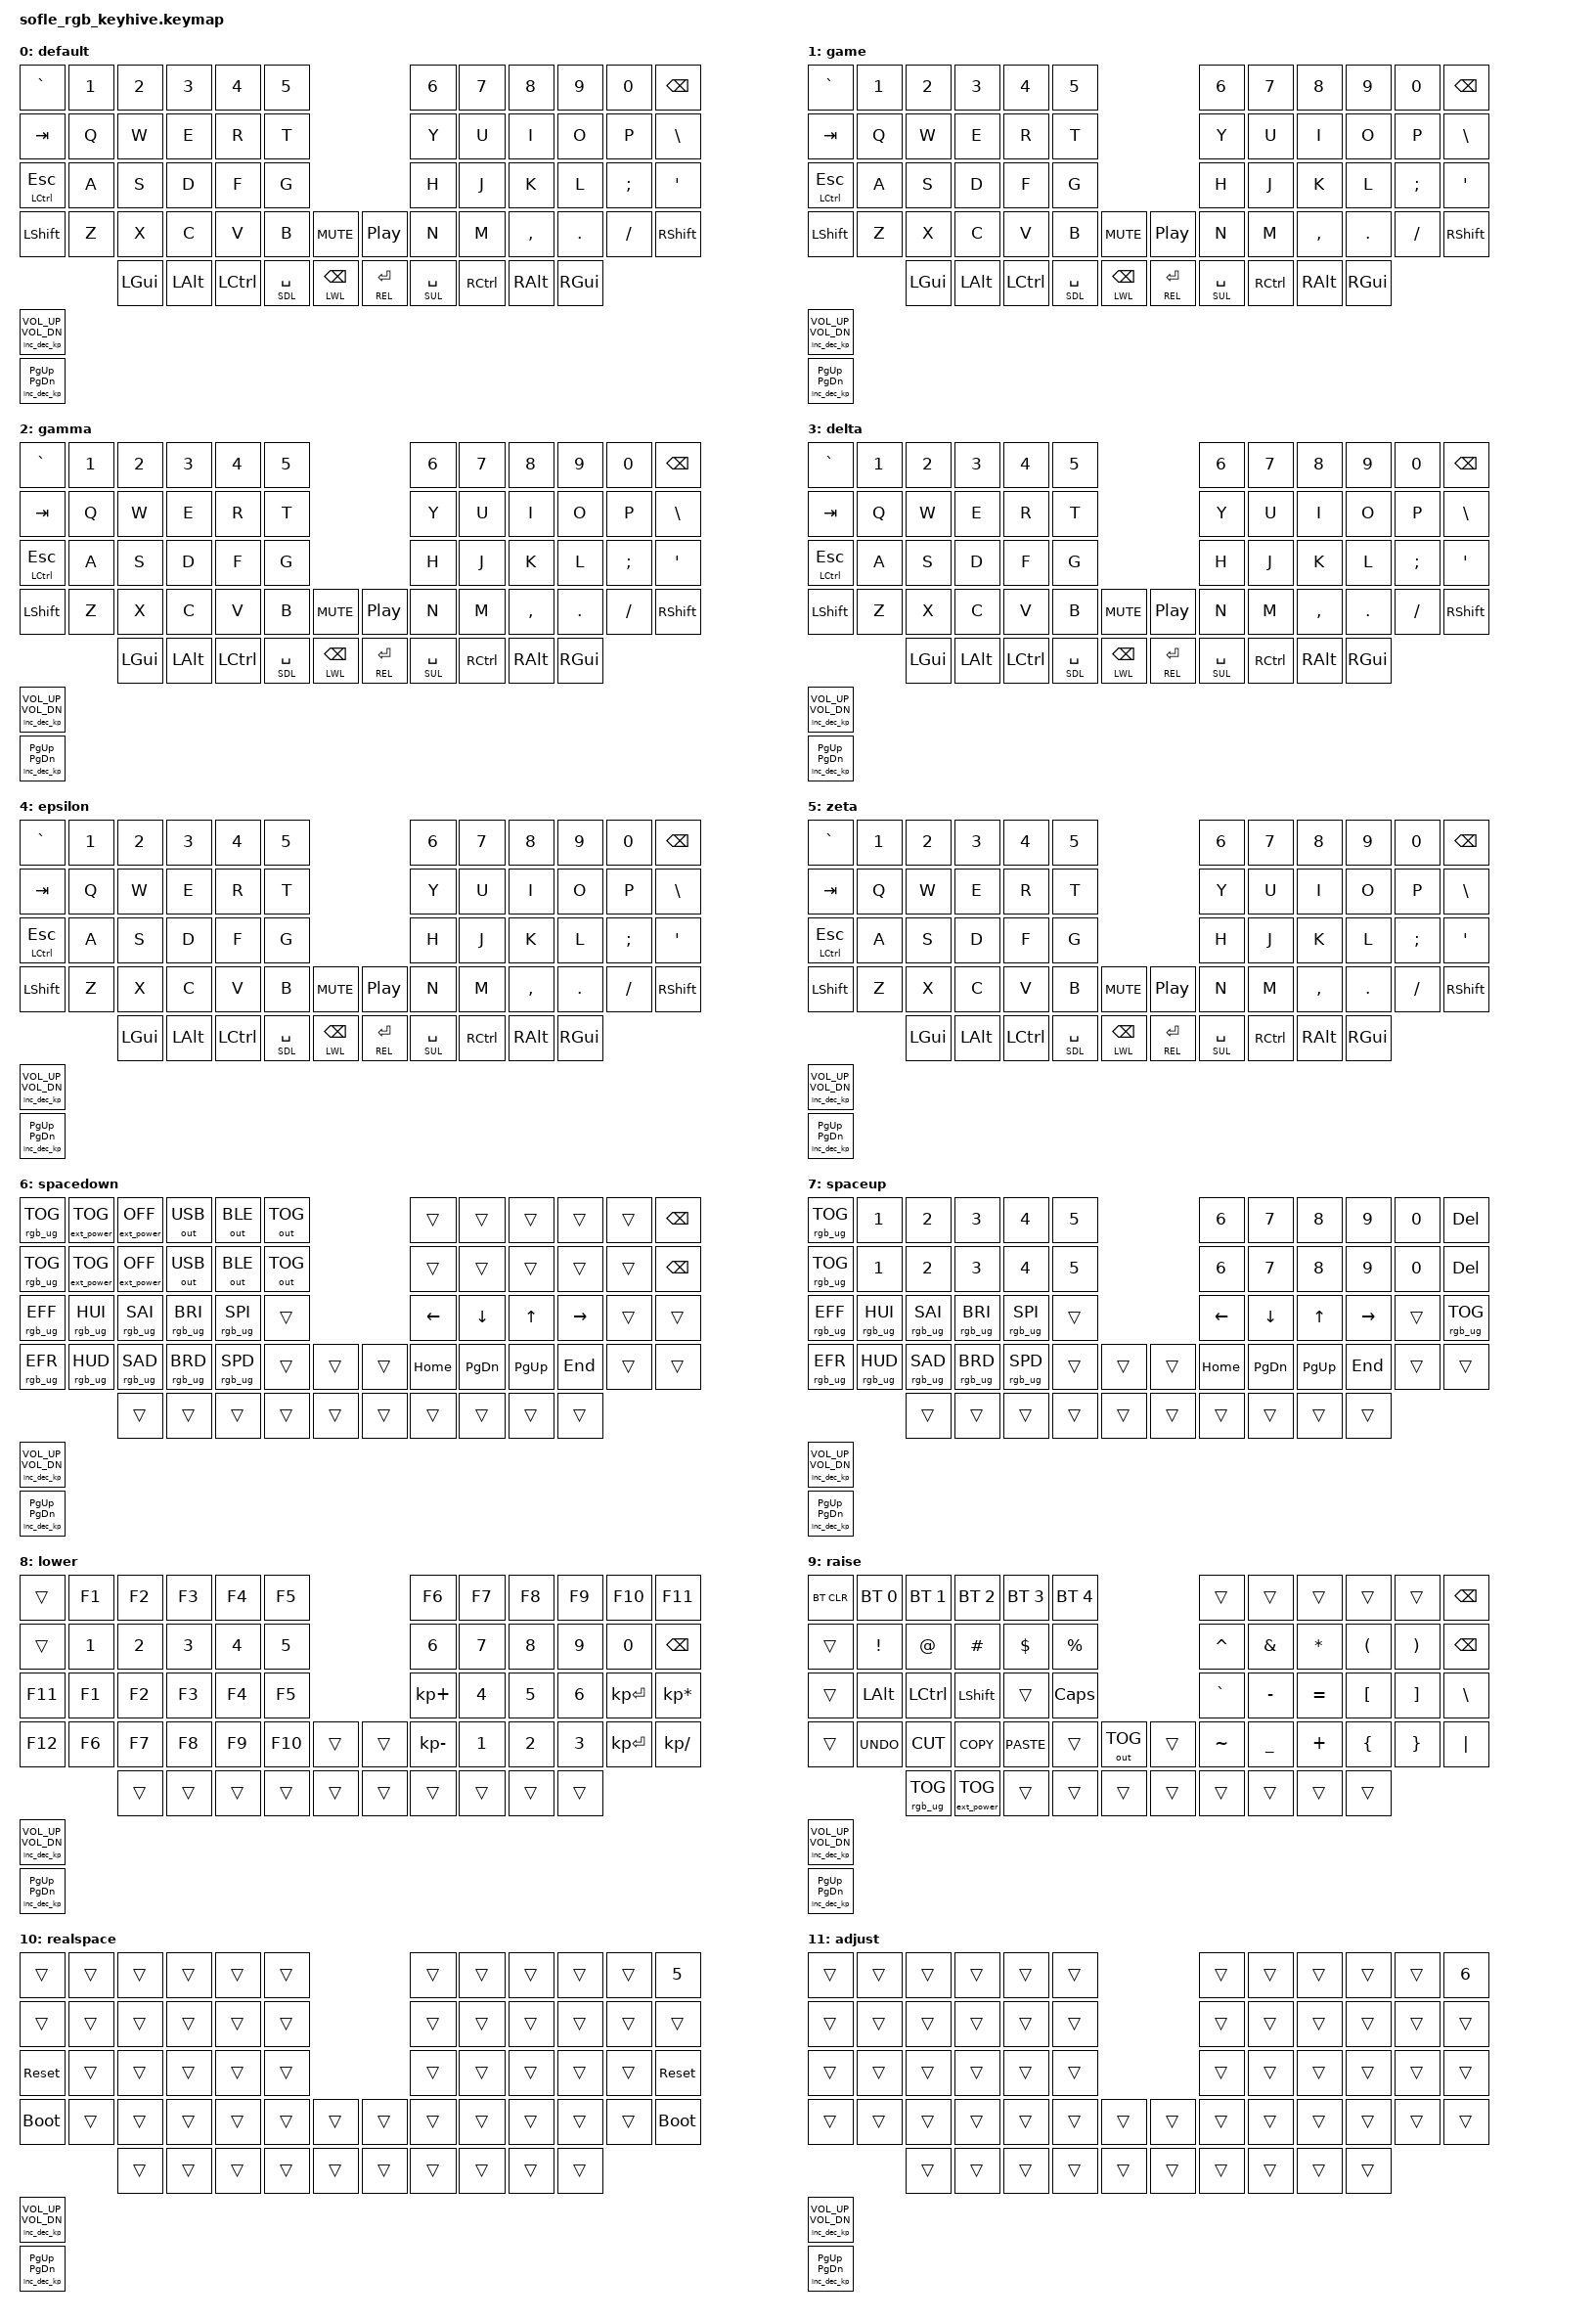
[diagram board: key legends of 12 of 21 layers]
/*
 * Copyright (c) 2020-2022 The ZMK Contributors
 *
 * SPDX-License-Identifier: MIT
 */

#include <zmk-helpers/helper.h>
#include <zmk-helpers/key-labels/sofle.h>
#include <behaviors.dtsi>
#include <dt-bindings/zmk/keys.h>
#include <dt-bindings/zmk/bt.h>
#include <dt-bindings/zmk/mouse.h>
#include <dt-bindings/zmk/outputs.h>
#include <dt-bindings/zmk/ext_power.h>
#include <dt-bindings/zmk/rgb.h>

#define DFL  0
#define GML  1
#define GAL  2
#define DTL  3
#define EPL  4
#define ZEL  5
#define SDL  6
#define SUL  7
#define LWL  8
#define REL  9
#define RSL 10
#define AJL 11
#define SSL 12
#define HSL 13
#define KSL 14
#define CSL 15
#define SLL 16
#define FSL 17
#define BHL 18
#define WHL 19
#define WPL 20

&mt {
  tapping-term-ms = <180>;
  flavor = "tap-preferred";
};
&lt {
  quick-tap-ms = <180>;
  flavor = "balanced";
};

ZMK_CONDITIONAL_LAYER(realspace_layer, SDL SUL, RSL)
ZMK_CONDITIONAL_LAYER(adjust_layer, LWL REL, AJL)
ZMK_CONDITIONAL_LAYER(subspace_layer, SDL LWL, SSL)
ZMK_CONDITIONAL_LAYER(hyperspace_layer, SUL REL, HSL)
ZMK_CONDITIONAL_LAYER(knownspace_layer, SDL REL, KSL)
ZMK_CONDITIONAL_LAYER(cyberspace_layer, LWL SUL, CSL)
ZMK_CONDITIONAL_LAYER(slipspace_layer, SSL REL, SLL)
ZMK_CONDITIONAL_LAYER(foldspace_layer, LWL HSL, FSL)
ZMK_CONDITIONAL_LAYER(blackhole_layer, SSL SUL, BHL)
ZMK_CONDITIONAL_LAYER(whitehole_layer, SDL HSL, WHL)
ZMK_CONDITIONAL_LAYER(warp_layer, SSL HSL, WPL)

ZMK_LAYER(default,
//    ┌───────────────┬────────┬──────────┬──────────┬───────────┬───────────────┐                            ┌───────────────┬───────────┬───────────┬──────────┬──────────┬───────────┐
//    │   &kp GRAVE   │ &kp N1 │  &kp N2  │  &kp N3  │  &kp N4   │    &kp N5     │                            │    &kp N6     │  &kp N7   │  &kp N8   │  &kp N9  │  &kp N0  │ &kp BSPC  │
//    ├───────────────┼────────┼──────────┼──────────┼───────────┼───────────────┤                            ├───────────────┼───────────┼───────────┼──────────┼──────────┼───────────┤
//    │    &kp TAB    │ &kp Q  │  &kp W   │  &kp E   │   &kp R   │     &kp T     │                            │     &kp Y     │   &kp U   │   &kp I   │  &kp O   │  &kp P   │ &kp BSLH  │
//    ├───────────────┼────────┼──────────┼──────────┼───────────┼───────────────┤                            ├───────────────┼───────────┼───────────┼──────────┼──────────┼───────────┤
//    │ &mt LCTRL ESC │ &kp A  │  &kp S   │  &kp D   │   &kp F   │     &kp G     │                            │     &kp H     │   &kp J   │   &kp K   │  &kp L   │ &kp SEMI │  &kp SQT  │
//    ├───────────────┼────────┼──────────┼──────────┼───────────┼───────────────┼──────────────┬─────────────┼───────────────┼───────────┼───────────┼──────────┼──────────┼───────────┤
//    │   &kp LSHFT   │ &kp Z  │  &kp X   │  &kp C   │   &kp V   │     &kp B     │  &kp C_MUTE  │  &kp C_PP   │     &kp N     │   &kp M   │ &kp COMMA │ &kp DOT  │ &kp FSLH │ &kp RSHFT │
//    └───────────────┴────────┼──────────┼──────────┼───────────┼───────────────┼──────────────┼─────────────┼───────────────┼───────────┼───────────┼──────────┼──────────┴───────────┘
//                             │ &kp LGUI │ &kp LALT │ &kp LCTRL │ &lt SDL SPACE │ &lt LWL BSPC │ &lt REL RET │ &lt SUL SPACE │ &kp RCTRL │ &kp RALT  │ &kp RGUI │                       
//                             └──────────┴──────────┴───────────┴───────────────┴──────────────┴─────────────┴───────────────┴───────────┴───────────┴──────────┘                       
        //
  &kp GRAVE       &kp N1   &kp N2     &kp N3     &kp N4      &kp N5                                       &kp N6          &kp N7      &kp N8      &kp N9     &kp N0     &kp BSPC 
  &kp TAB         &kp Q    &kp W      &kp E      &kp R       &kp T                                        &kp Y           &kp U       &kp I       &kp O      &kp P      &kp BSLH 
  &mt LCTRL ESC   &kp A    &kp S      &kp D      &kp F       &kp G                                        &kp H           &kp J       &kp K       &kp L      &kp SEMI   &kp SQT  
  &kp LSHFT       &kp Z    &kp X      &kp C      &kp V       &kp B           &kp C_MUTE     &kp C_PP      &kp N           &kp M       &kp COMMA   &kp DOT    &kp FSLH   &kp RSHFT
                           &kp LGUI   &kp LALT   &kp LCTRL   &lt SDL SPACE   &lt LWL BSPC   &lt REL RET   &lt SUL SPACE   &kp RCTRL   &kp RALT    &kp RGUI                       
                           ,
        &inc_dec_kp C_VOL_UP C_VOL_DN
        &inc_dec_kp PG_UP PG_DN
)

ZMK_LAYER(game,
//    ┌───────────────┬────────┬──────────┬──────────┬───────────┬───────────────┐                            ┌───────────────┬───────────┬───────────┬──────────┬──────────┬───────────┐
//    │   &kp GRAVE   │ &kp N1 │  &kp N2  │  &kp N3  │  &kp N4   │    &kp N5     │                            │    &kp N6     │  &kp N7   │  &kp N8   │  &kp N9  │  &kp N0  │ &kp BSPC  │
//    ├───────────────┼────────┼──────────┼──────────┼───────────┼───────────────┤                            ├───────────────┼───────────┼───────────┼──────────┼──────────┼───────────┤
//    │    &kp TAB    │ &kp Q  │  &kp W   │  &kp E   │   &kp R   │     &kp T     │                            │     &kp Y     │   &kp U   │   &kp I   │  &kp O   │  &kp P   │ &kp BSLH  │
//    ├───────────────┼────────┼──────────┼──────────┼───────────┼───────────────┤                            ├───────────────┼───────────┼───────────┼──────────┼──────────┼───────────┤
//    │ &mt LCTRL ESC │ &kp A  │  &kp S   │  &kp D   │   &kp F   │     &kp G     │                            │     &kp H     │   &kp J   │   &kp K   │  &kp L   │ &kp SEMI │  &kp SQT  │
//    ├───────────────┼────────┼──────────┼──────────┼───────────┼───────────────┼──────────────┬─────────────┼───────────────┼───────────┼───────────┼──────────┼──────────┼───────────┤
//    │   &kp LSHFT   │ &kp Z  │  &kp X   │  &kp C   │   &kp V   │     &kp B     │  &kp C_MUTE  │  &kp C_PP   │     &kp N     │   &kp M   │ &kp COMMA │ &kp DOT  │ &kp FSLH │ &kp RSHFT │
//    └───────────────┴────────┼──────────┼──────────┼───────────┼───────────────┼──────────────┼─────────────┼───────────────┼───────────┼───────────┼──────────┼──────────┴───────────┘
//                             │ &kp LGUI │ &kp LALT │ &kp LCTRL │ &lt SDL SPACE │ &lt LWL BSPC │ &lt REL RET │ &lt SUL SPACE │ &kp RCTRL │ &kp RALT  │ &kp RGUI │                       
//                             └──────────┴──────────┴───────────┴───────────────┴──────────────┴─────────────┴───────────────┴───────────┴───────────┴──────────┘                       
        //
  &kp GRAVE       &kp N1   &kp N2     &kp N3     &kp N4      &kp N5                                       &kp N6          &kp N7      &kp N8      &kp N9     &kp N0     &kp BSPC 
  &kp TAB         &kp Q    &kp W      &kp E      &kp R       &kp T                                        &kp Y           &kp U       &kp I       &kp O      &kp P      &kp BSLH 
  &mt LCTRL ESC   &kp A    &kp S      &kp D      &kp F       &kp G                                        &kp H           &kp J       &kp K       &kp L      &kp SEMI   &kp SQT  
  &kp LSHFT       &kp Z    &kp X      &kp C      &kp V       &kp B           &kp C_MUTE     &kp C_PP      &kp N           &kp M       &kp COMMA   &kp DOT    &kp FSLH   &kp RSHFT
                           &kp LGUI   &kp LALT   &kp LCTRL   &lt SDL SPACE   &lt LWL BSPC   &lt REL RET   &lt SUL SPACE   &kp RCTRL   &kp RALT    &kp RGUI                       
                           ,
        &inc_dec_kp C_VOL_UP C_VOL_DN
        &inc_dec_kp PG_UP PG_DN
        )

ZMK_LAYER(gamma,
//    ┌───────────────┬────────┬──────────┬──────────┬───────────┬───────────────┐                            ┌───────────────┬───────────┬───────────┬──────────┬──────────┬───────────┐
//    │   &kp GRAVE   │ &kp N1 │  &kp N2  │  &kp N3  │  &kp N4   │    &kp N5     │                            │    &kp N6     │  &kp N7   │  &kp N8   │  &kp N9  │  &kp N0  │ &kp BSPC  │
//    ├───────────────┼────────┼──────────┼──────────┼───────────┼───────────────┤                            ├───────────────┼───────────┼───────────┼──────────┼──────────┼───────────┤
//    │    &kp TAB    │ &kp Q  │  &kp W   │  &kp E   │   &kp R   │     &kp T     │                            │     &kp Y     │   &kp U   │   &kp I   │  &kp O   │  &kp P   │ &kp BSLH  │
//    ├───────────────┼────────┼──────────┼──────────┼───────────┼───────────────┤                            ├───────────────┼───────────┼───────────┼──────────┼──────────┼───────────┤
//    │ &mt LCTRL ESC │ &kp A  │  &kp S   │  &kp D   │   &kp F   │     &kp G     │                            │     &kp H     │   &kp J   │   &kp K   │  &kp L   │ &kp SEMI │  &kp SQT  │
//    ├───────────────┼────────┼──────────┼──────────┼───────────┼───────────────┼──────────────┬─────────────┼───────────────┼───────────┼───────────┼──────────┼──────────┼───────────┤
//    │   &kp LSHFT   │ &kp Z  │  &kp X   │  &kp C   │   &kp V   │     &kp B     │  &kp C_MUTE  │  &kp C_PP   │     &kp N     │   &kp M   │ &kp COMMA │ &kp DOT  │ &kp FSLH │ &kp RSHFT │
//    └───────────────┴────────┼──────────┼──────────┼───────────┼───────────────┼──────────────┼─────────────┼───────────────┼───────────┼───────────┼──────────┼──────────┴───────────┘
//                             │ &kp LGUI │ &kp LALT │ &kp LCTRL │ &lt SDL SPACE │ &lt LWL BSPC │ &lt REL RET │ &lt SUL SPACE │ &kp RCTRL │ &kp RALT  │ &kp RGUI │                       
//                             └──────────┴──────────┴───────────┴───────────────┴──────────────┴─────────────┴───────────────┴───────────┴───────────┴──────────┘                       
        //
  &kp GRAVE       &kp N1   &kp N2     &kp N3     &kp N4      &kp N5                                       &kp N6          &kp N7      &kp N8      &kp N9     &kp N0     &kp BSPC 
  &kp TAB         &kp Q    &kp W      &kp E      &kp R       &kp T                                        &kp Y           &kp U       &kp I       &kp O      &kp P      &kp BSLH 
  &mt LCTRL ESC   &kp A    &kp S      &kp D      &kp F       &kp G                                        &kp H           &kp J       &kp K       &kp L      &kp SEMI   &kp SQT  
  &kp LSHFT       &kp Z    &kp X      &kp C      &kp V       &kp B           &kp C_MUTE     &kp C_PP      &kp N           &kp M       &kp COMMA   &kp DOT    &kp FSLH   &kp RSHFT
                           &kp LGUI   &kp LALT   &kp LCTRL   &lt SDL SPACE   &lt LWL BSPC   &lt REL RET   &lt SUL SPACE   &kp RCTRL   &kp RALT    &kp RGUI                       
,
  &inc_dec_kp C_VOL_UP C_VOL_DN
  &inc_dec_kp PG_UP PG_DN
)

ZMK_LAYER(delta,
//    ┌───────────────┬────────┬──────────┬──────────┬───────────┬───────────────┐                            ┌───────────────┬───────────┬───────────┬──────────┬──────────┬───────────┐
//    │   &kp GRAVE   │ &kp N1 │  &kp N2  │  &kp N3  │  &kp N4   │    &kp N5     │                            │    &kp N6     │  &kp N7   │  &kp N8   │  &kp N9  │  &kp N0  │ &kp BSPC  │
//    ├───────────────┼────────┼──────────┼──────────┼───────────┼───────────────┤                            ├───────────────┼───────────┼───────────┼──────────┼──────────┼───────────┤
//    │    &kp TAB    │ &kp Q  │  &kp W   │  &kp E   │   &kp R   │     &kp T     │                            │     &kp Y     │   &kp U   │   &kp I   │  &kp O   │  &kp P   │ &kp BSLH  │
//    ├───────────────┼────────┼──────────┼──────────┼───────────┼───────────────┤                            ├───────────────┼───────────┼───────────┼──────────┼──────────┼───────────┤
//    │ &mt LCTRL ESC │ &kp A  │  &kp S   │  &kp D   │   &kp F   │     &kp G     │                            │     &kp H     │   &kp J   │   &kp K   │  &kp L   │ &kp SEMI │  &kp SQT  │
//    ├───────────────┼────────┼──────────┼──────────┼───────────┼───────────────┼──────────────┬─────────────┼───────────────┼───────────┼───────────┼──────────┼──────────┼───────────┤
//    │   &kp LSHFT   │ &kp Z  │  &kp X   │  &kp C   │   &kp V   │     &kp B     │  &kp C_MUTE  │  &kp C_PP   │     &kp N     │   &kp M   │ &kp COMMA │ &kp DOT  │ &kp FSLH │ &kp RSHFT │
//    └───────────────┴────────┼──────────┼──────────┼───────────┼───────────────┼──────────────┼─────────────┼───────────────┼───────────┼───────────┼──────────┼──────────┴───────────┘
//                             │ &kp LGUI │ &kp LALT │ &kp LCTRL │ &lt SDL SPACE │ &lt LWL BSPC │ &lt REL RET │ &lt SUL SPACE │ &kp RCTRL │ &kp RALT  │ &kp RGUI │                       
//                             └──────────┴──────────┴───────────┴───────────────┴──────────────┴─────────────┴───────────────┴───────────┴───────────┴──────────┘                       
        //
  &kp GRAVE       &kp N1   &kp N2     &kp N3     &kp N4      &kp N5                                       &kp N6          &kp N7      &kp N8      &kp N9     &kp N0     &kp BSPC 
  &kp TAB         &kp Q    &kp W      &kp E      &kp R       &kp T                                        &kp Y           &kp U       &kp I       &kp O      &kp P      &kp BSLH 
  &mt LCTRL ESC   &kp A    &kp S      &kp D      &kp F       &kp G                                        &kp H           &kp J       &kp K       &kp L      &kp SEMI   &kp SQT  
  &kp LSHFT       &kp Z    &kp X      &kp C      &kp V       &kp B           &kp C_MUTE     &kp C_PP      &kp N           &kp M       &kp COMMA   &kp DOT    &kp FSLH   &kp RSHFT
                           &kp LGUI   &kp LALT   &kp LCTRL   &lt SDL SPACE   &lt LWL BSPC   &lt REL RET   &lt SUL SPACE   &kp RCTRL   &kp RALT    &kp RGUI                       
,
  &inc_dec_kp C_VOL_UP C_VOL_DN
  &inc_dec_kp PG_UP PG_DN
)

ZMK_LAYER(epsilon,
//    ┌───────────────┬────────┬──────────┬──────────┬───────────┬───────────────┐                            ┌───────────────┬───────────┬───────────┬──────────┬──────────┬───────────┐
//    │   &kp GRAVE   │ &kp N1 │  &kp N2  │  &kp N3  │  &kp N4   │    &kp N5     │                            │    &kp N6     │  &kp N7   │  &kp N8   │  &kp N9  │  &kp N0  │ &kp BSPC  │
//    ├───────────────┼────────┼──────────┼──────────┼───────────┼───────────────┤                            ├───────────────┼───────────┼───────────┼──────────┼──────────┼───────────┤
//    │    &kp TAB    │ &kp Q  │  &kp W   │  &kp E   │   &kp R   │     &kp T     │                            │     &kp Y     │   &kp U   │   &kp I   │  &kp O   │  &kp P   │ &kp BSLH  │
//    ├───────────────┼────────┼──────────┼──────────┼───────────┼───────────────┤                            ├───────────────┼───────────┼───────────┼──────────┼──────────┼───────────┤
//    │ &mt LCTRL ESC │ &kp A  │  &kp S   │  &kp D   │   &kp F   │     &kp G     │                            │     &kp H     │   &kp J   │   &kp K   │  &kp L   │ &kp SEMI │  &kp SQT  │
//    ├───────────────┼────────┼──────────┼──────────┼───────────┼───────────────┼──────────────┬─────────────┼───────────────┼───────────┼───────────┼──────────┼──────────┼───────────┤
//    │   &kp LSHFT   │ &kp Z  │  &kp X   │  &kp C   │   &kp V   │     &kp B     │  &kp C_MUTE  │  &kp C_PP   │     &kp N     │   &kp M   │ &kp COMMA │ &kp DOT  │ &kp FSLH │ &kp RSHFT │
//    └───────────────┴────────┼──────────┼──────────┼───────────┼───────────────┼──────────────┼─────────────┼───────────────┼───────────┼───────────┼──────────┼──────────┴───────────┘
//                             │ &kp LGUI │ &kp LALT │ &kp LCTRL │ &lt SDL SPACE │ &lt LWL BSPC │ &lt REL RET │ &lt SUL SPACE │ &kp RCTRL │ &kp RALT  │ &kp RGUI │                       
//                             └──────────┴──────────┴───────────┴───────────────┴──────────────┴─────────────┴───────────────┴───────────┴───────────┴──────────┘                       
        //
  &kp GRAVE       &kp N1   &kp N2     &kp N3     &kp N4      &kp N5                                       &kp N6          &kp N7      &kp N8      &kp N9     &kp N0     &kp BSPC 
  &kp TAB         &kp Q    &kp W      &kp E      &kp R       &kp T                                        &kp Y           &kp U       &kp I       &kp O      &kp P      &kp BSLH 
  &mt LCTRL ESC   &kp A    &kp S      &kp D      &kp F       &kp G                                        &kp H           &kp J       &kp K       &kp L      &kp SEMI   &kp SQT  
  &kp LSHFT       &kp Z    &kp X      &kp C      &kp V       &kp B           &kp C_MUTE     &kp C_PP      &kp N           &kp M       &kp COMMA   &kp DOT    &kp FSLH   &kp RSHFT
                           &kp LGUI   &kp LALT   &kp LCTRL   &lt SDL SPACE   &lt LWL BSPC   &lt REL RET   &lt SUL SPACE   &kp RCTRL   &kp RALT    &kp RGUI                       
,
        &inc_dec_kp C_VOL_UP C_VOL_DN
        &inc_dec_kp PG_UP PG_DN
)

ZMK_LAYER(zeta,
//    ┌───────────────┬────────┬──────────┬──────────┬───────────┬───────────────┐                            ┌───────────────┬───────────┬───────────┬──────────┬──────────┬───────────┐
//    │   &kp GRAVE   │ &kp N1 │  &kp N2  │  &kp N3  │  &kp N4   │    &kp N5     │                            │    &kp N6     │  &kp N7   │  &kp N8   │  &kp N9  │  &kp N0  │ &kp BSPC  │
//    ├───────────────┼────────┼──────────┼──────────┼───────────┼───────────────┤                            ├───────────────┼───────────┼───────────┼──────────┼──────────┼───────────┤
//    │    &kp TAB    │ &kp Q  │  &kp W   │  &kp E   │   &kp R   │     &kp T     │                            │     &kp Y     │   &kp U   │   &kp I   │  &kp O   │  &kp P   │ &kp BSLH  │
//    ├───────────────┼────────┼──────────┼──────────┼───────────┼───────────────┤                            ├───────────────┼───────────┼───────────┼──────────┼──────────┼───────────┤
//    │ &mt LCTRL ESC │ &kp A  │  &kp S   │  &kp D   │   &kp F   │     &kp G     │                            │     &kp H     │   &kp J   │   &kp K   │  &kp L   │ &kp SEMI │  &kp SQT  │
//    ├───────────────┼────────┼──────────┼──────────┼───────────┼───────────────┼──────────────┬─────────────┼───────────────┼───────────┼───────────┼──────────┼──────────┼───────────┤
//    │   &kp LSHFT   │ &kp Z  │  &kp X   │  &kp C   │   &kp V   │     &kp B     │  &kp C_MUTE  │  &kp C_PP   │     &kp N     │   &kp M   │ &kp COMMA │ &kp DOT  │ &kp FSLH │ &kp RSHFT │
//    └───────────────┴────────┼──────────┼──────────┼───────────┼───────────────┼──────────────┼─────────────┼───────────────┼───────────┼───────────┼──────────┼──────────┴───────────┘
//                             │ &kp LGUI │ &kp LALT │ &kp LCTRL │ &lt SDL SPACE │ &lt LWL BSPC │ &lt REL RET │ &lt SUL SPACE │ &kp RCTRL │ &kp RALT  │ &kp RGUI │                       
//                             └──────────┴──────────┴───────────┴───────────────┴──────────────┴─────────────┴───────────────┴───────────┴───────────┴──────────┘                       
        //
  &kp GRAVE       &kp N1   &kp N2     &kp N3     &kp N4      &kp N5                                       &kp N6          &kp N7      &kp N8      &kp N9     &kp N0     &kp BSPC 
  &kp TAB         &kp Q    &kp W      &kp E      &kp R       &kp T                                        &kp Y           &kp U       &kp I       &kp O      &kp P      &kp BSLH 
  &mt LCTRL ESC   &kp A    &kp S      &kp D      &kp F       &kp G                                        &kp H           &kp J       &kp K       &kp L      &kp SEMI   &kp SQT  
  &kp LSHFT       &kp Z    &kp X      &kp C      &kp V       &kp B           &kp C_MUTE     &kp C_PP      &kp N           &kp M       &kp COMMA   &kp DOT    &kp FSLH   &kp RSHFT
                           &kp LGUI   &kp LALT   &kp LCTRL   &lt SDL SPACE   &lt LWL BSPC   &lt REL RET   &lt SUL SPACE   &kp RCTRL   &kp RALT    &kp RGUI                       
,
        &inc_dec_kp C_VOL_UP C_VOL_DN
        &inc_dec_kp PG_UP PG_DN
)

ZMK_LAYER(spacedown,
//    ┌─────────────────┬───────────────────┬───────────────────┬─────────────────┬─────────────────┬──────────────┐                 ┌──────────┬───────────┬───────────┬───────────┬────────┬──────────┐
//    │ &rgb_ug RGB_TOG │ &ext_power EP_TOG │ &ext_power EP_OFF │  &out OUT_USB   │  &out OUT_BLE   │ &out OUT_TOG │                 │  &trans  │  &trans   │  &trans   │  &trans   │ &trans │ &kp BSPC │
//    ├─────────────────┼───────────────────┼───────────────────┼─────────────────┼─────────────────┼──────────────┤                 ├──────────┼───────────┼───────────┼───────────┼────────┼──────────┤
//    │ &rgb_ug RGB_TOG │ &ext_power EP_TOG │ &ext_power EP_OFF │  &out OUT_USB   │  &out OUT_BLE   │ &out OUT_TOG │                 │  &trans  │  &trans   │  &trans   │  &trans   │ &trans │ &kp BSPC │
//    ├─────────────────┼───────────────────┼───────────────────┼─────────────────┼─────────────────┼──────────────┤                 ├──────────┼───────────┼───────────┼───────────┼────────┼──────────┤
//    │ &rgb_ug RGB_EFF │  &rgb_ug RGB_HUI  │  &rgb_ug RGB_SAI  │ &rgb_ug RGB_BRI │ &rgb_ug RGB_SPI │    &trans    │                 │ &kp LEFT │ &kp DOWN  │  &kp UP   │ &kp RIGHT │ &trans │  &trans  │
//    ├─────────────────┼───────────────────┼───────────────────┼─────────────────┼─────────────────┼──────────────┼────────┬────────┼──────────┼───────────┼───────────┼───────────┼────────┼──────────┤
//    │ &rgb_ug RGB_EFR │  &rgb_ug RGB_HUD  │  &rgb_ug RGB_SAD  │ &rgb_ug RGB_BRD │ &rgb_ug RGB_SPD │    &trans    │ &trans │ &trans │ &kp HOME │ &kp PG_DN │ &kp PG_UP │  &kp END  │ &trans │  &trans  │
//    └─────────────────┴───────────────────┼───────────────────┼─────────────────┼─────────────────┼──────────────┼────────┼────────┼──────────┼───────────┼───────────┼───────────┼────────┴──────────┘
//                                          │      &trans       │     &trans      │     &trans      │    &trans    │ &trans │ &trans │  &trans  │  &trans   │  &trans   │  &trans   │                    
//                                          └───────────────────┴─────────────────┴─────────────────┴──────────────┴────────┴────────┴──────────┴───────────┴───────────┴───────────┘                    
        //
  &rgb_ug RGB_TOG   &ext_power EP_TOG   &ext_power EP_OFF   &out OUT_USB      &out OUT_BLE      &out OUT_TOG                     &trans     &trans      &trans      &trans      &trans   &kp BSPC
  &rgb_ug RGB_TOG   &ext_power EP_TOG   &ext_power EP_OFF   &out OUT_USB      &out OUT_BLE      &out OUT_TOG                     &trans     &trans      &trans      &trans      &trans   &kp BSPC
  &rgb_ug RGB_EFF   &rgb_ug RGB_HUI     &rgb_ug RGB_SAI     &rgb_ug RGB_BRI   &rgb_ug RGB_SPI   &trans                           &kp LEFT   &kp DOWN    &kp UP      &kp RIGHT   &trans   &trans  
  &rgb_ug RGB_EFR   &rgb_ug RGB_HUD     &rgb_ug RGB_SAD     &rgb_ug RGB_BRD   &rgb_ug RGB_SPD   &trans         &trans   &trans   &kp HOME   &kp PG_DN   &kp PG_UP   &kp END     &trans   &trans  
                                        &trans              &trans            &trans            &trans         &trans   &trans   &trans     &trans      &trans      &trans                       
,
        &inc_dec_kp C_VOL_UP C_VOL_DN
        &inc_dec_kp PG_UP PG_DN
)

ZMK_LAYER(spaceup,
//    ┌─────────────────┬─────────────────┬─────────────────┬─────────────────┬─────────────────┬────────┐                 ┌──────────┬───────────┬───────────┬───────────┬────────┬─────────────────┐
//    │ &rgb_ug RGB_TOG │     &kp N1      │     &kp N2      │     &kp N3      │     &kp N4      │ &kp N5 │                 │  &kp N6  │  &kp N7   │  &kp N8   │  &kp N9   │ &kp N0 │     &kp DEL     │
//    ├─────────────────┼─────────────────┼─────────────────┼─────────────────┼─────────────────┼────────┤                 ├──────────┼───────────┼───────────┼───────────┼────────┼─────────────────┤
//    │ &rgb_ug RGB_TOG │     &kp N1      │     &kp N2      │     &kp N3      │     &kp N4      │ &kp N5 │                 │  &kp N6  │  &kp N7   │  &kp N8   │  &kp N9   │ &kp N0 │     &kp DEL     │
//    ├─────────────────┼─────────────────┼─────────────────┼─────────────────┼─────────────────┼────────┤                 ├──────────┼───────────┼───────────┼───────────┼────────┼─────────────────┤
//    │ &rgb_ug RGB_EFF │ &rgb_ug RGB_HUI │ &rgb_ug RGB_SAI │ &rgb_ug RGB_BRI │ &rgb_ug RGB_SPI │ &trans │                 │ &kp LEFT │ &kp DOWN  │  &kp UP   │ &kp RIGHT │ &trans │ &rgb_ug RGB_TOG │
//    ├─────────────────┼─────────────────┼─────────────────┼─────────────────┼─────────────────┼────────┼────────┬────────┼──────────┼───────────┼───────────┼───────────┼────────┼─────────────────┤
//    │ &rgb_ug RGB_EFR │ &rgb_ug RGB_HUD │ &rgb_ug RGB_SAD │ &rgb_ug RGB_BRD │ &rgb_ug RGB_SPD │ &trans │ &trans │ &trans │ &kp HOME │ &kp PG_DN │ &kp PG_UP │  &kp END  │ &trans │     &trans      │
//    └─────────────────┴─────────────────┼─────────────────┼─────────────────┼─────────────────┼────────┼────────┼────────┼──────────┼───────────┼───────────┼───────────┼────────┴─────────────────┘
//                                        │     &trans      │     &trans      │     &trans      │ &trans │ &trans │ &trans │  &trans  │  &trans   │  &trans   │  &trans   │                           
//                                        └─────────────────┴─────────────────┴─────────────────┴────────┴────────┴────────┴──────────┴───────────┴───────────┴───────────┘                           
        //
  &rgb_ug RGB_TOG   &kp N1            &kp N2            &kp N3            &kp N4            &kp N5                     &kp N6     &kp N7      &kp N8      &kp N9      &kp N0   &kp DEL        
  &rgb_ug RGB_TOG   &kp N1            &kp N2            &kp N3            &kp N4            &kp N5                     &kp N6     &kp N7      &kp N8      &kp N9      &kp N0   &kp DEL        
  &rgb_ug RGB_EFF   &rgb_ug RGB_HUI   &rgb_ug RGB_SAI   &rgb_ug RGB_BRI   &rgb_ug RGB_SPI   &trans                     &kp LEFT   &kp DOWN    &kp UP      &kp RIGHT   &trans   &rgb_ug RGB_TOG
  &rgb_ug RGB_EFR   &rgb_ug RGB_HUD   &rgb_ug RGB_SAD   &rgb_ug RGB_BRD   &rgb_ug RGB_SPD   &trans   &trans   &trans   &kp HOME   &kp PG_DN   &kp PG_UP   &kp END     &trans   &trans         
                                      &trans            &trans            &trans            &trans   &trans   &trans   &trans     &trans      &trans      &trans                              
,
  &inc_dec_kp C_VOL_UP C_VOL_DN
  &inc_dec_kp PG_UP PG_DN
)

ZMK_LAYER(lower,
//    ┌─────────┬────────┬────────┬────────┬────────┬─────────┐                 ┌──────────────┬────────┬────────┬────────┬──────────────┬─────────────────┐
//    │ &trans  │ &kp F1 │ &kp F2 │ &kp F3 │ &kp F4 │ &kp F5  │                 │    &kp F6    │ &kp F7 │ &kp F8 │ &kp F9 │   &kp F10    │     &kp F11     │
//    ├─────────┼────────┼────────┼────────┼────────┼─────────┤                 ├──────────────┼────────┼────────┼────────┼──────────────┼─────────────────┤
//    │ &trans  │ &kp N1 │ &kp N2 │ &kp N3 │ &kp N4 │ &kp N5  │                 │    &kp N6    │ &kp N7 │ &kp N8 │ &kp N9 │    &kp N0    │    &kp BSPC     │
//    ├─────────┼────────┼────────┼────────┼────────┼─────────┤                 ├──────────────┼────────┼────────┼────────┼──────────────┼─────────────────┤
//    │ &kp F11 │ &kp F1 │ &kp F2 │ &kp F3 │ &kp F4 │ &kp F5  │                 │ &kp KP_PLUS  │ &kp N4 │ &kp N5 │ &kp N6 │ &kp KP_ENTER │ &kp KP_MULTIPLY │
//    ├─────────┼────────┼────────┼────────┼────────┼─────────┼────────┬────────┼──────────────┼────────┼────────┼────────┼──────────────┼─────────────────┤
//    │ &kp F12 │ &kp F6 │ &kp F7 │ &kp F8 │ &kp F9 │ &kp F10 │ &trans │ &trans │ &kp KP_MINUS │ &kp N1 │ &kp N2 │ &kp N3 │ &kp KP_ENTER │  &kp KP_DIVIDE  │
//    └─────────┴────────┼────────┼────────┼────────┼─────────┼────────┼────────┼──────────────┼────────┼────────┼────────┼──────────────┴─────────────────┘
//                       │ &trans │ &trans │ &trans │ &trans  │ &trans │ &trans │    &trans    │ &trans │ &trans │ &trans │                                 
//                       └────────┴────────┴────────┴─────────┴────────┴────────┴──────────────┴────────┴────────┴────────┘                                 
        //
  &trans    &kp F1   &kp F2   &kp F3   &kp F4   &kp F5                      &kp F6         &kp F7   &kp F8   &kp F9   &kp F10        &kp F11        
  &trans    &kp N1   &kp N2   &kp N3   &kp N4   &kp N5                      &kp N6         &kp N7   &kp N8   &kp N9   &kp N0         &kp BSPC       
  &kp F11   &kp F1   &kp F2   &kp F3   &kp F4   &kp F5                      &kp KP_PLUS    &kp N4   &kp N5   &kp N6   &kp KP_ENTER   &kp KP_MULTIPLY
  &kp F12   &kp F6   &kp F7   &kp F8   &kp F9   &kp F10   &trans   &trans   &kp KP_MINUS   &kp N1   &kp N2   &kp N3   &kp KP_ENTER   &kp KP_DIVIDE  
                     &trans   &trans   &trans   &trans    &trans   &trans   &trans         &trans   &trans   &trans                                 
,
  &inc_dec_kp C_VOL_UP C_VOL_DN
  &inc_dec_kp PG_UP PG_DN
)

ZMK_LAYER(raise,
//    ┌────────────┬──────────────┬─────────────────┬───────────────────┬──────────────┬──────────────┐                       ┌───────────┬───────────┬───────────┬──────────┬──────────┬──────────┐
//    │ &bt BT_CLR │ &bt BT_SEL 0 │  &bt BT_SEL 1   │   &bt BT_SEL 2    │ &bt BT_SEL 3 │ &bt BT_SEL 4 │                       │  &trans   │  &trans   │  &trans   │  &trans  │  &trans  │ &kp BSPC │
//    ├────────────┼──────────────┼─────────────────┼───────────────────┼──────────────┼──────────────┤                       ├───────────┼───────────┼───────────┼──────────┼──────────┼──────────┤
//    │   &trans   │   &kp EXCL   │     &kp AT      │     &kp HASH      │   &kp DLLR   │  &kp PRCNT   │                       │ &kp CARET │ &kp AMPS  │ &kp ASTRK │ &kp LPAR │ &kp RPAR │ &kp BSPC │
//    ├────────────┼──────────────┼─────────────────┼───────────────────┼──────────────┼──────────────┤                       ├───────────┼───────────┼───────────┼──────────┼──────────┼──────────┤
//    │   &trans   │   &kp LALT   │    &kp LCTRL    │     &kp LSHFT     │    &trans    │   &kp CLCK   │                       │ &kp GRAVE │ &kp MINUS │ &kp EQUAL │ &kp LBKT │ &kp RBKT │ &kp BSLH │
//    ├────────────┼──────────────┼─────────────────┼───────────────────┼──────────────┼──────────────┼──────────────┬────────┼───────────┼───────────┼───────────┼──────────┼──────────┼──────────┤
//    │   &trans   │  &kp K_UNDO  │    &kp K_CUT    │    &kp K_COPY     │ &kp K_PASTE  │    &trans    │ &out OUT_TOG │ &trans │ &kp TILDE │ &kp UNDER │ &kp PLUS  │ &kp LBRC │ &kp RBRC │ &kp PIPE │
//    └────────────┴──────────────┼─────────────────┼───────────────────┼──────────────┼──────────────┼──────────────┼────────┼───────────┼───────────┼───────────┼──────────┼──────────┴──────────┘
//                                │ &rgb_ug RGB_TOG │ &ext_power EP_TOG │    &trans    │    &trans    │    &trans    │ &trans │  &trans   │  &trans   │  &trans   │  &trans  │                      
//                                └─────────────────┴───────────────────┴──────────────┴──────────────┴──────────────┴────────┴───────────┴───────────┴───────────┴──────────┘                      
        //
  &bt BT_CLR   &bt BT_SEL 0   &bt BT_SEL 1      &bt BT_SEL 2        &bt BT_SEL 3   &bt BT_SEL 4                           &trans      &trans      &trans      &trans     &trans     &kp BSPC
  &trans       &kp EXCL       &kp AT            &kp HASH            &kp DLLR       &kp PRCNT                              &kp CARET   &kp AMPS    &kp ASTRK   &kp LPAR   &kp RPAR   &kp BSPC
  &trans       &kp LALT       &kp LCTRL         &kp LSHFT           &trans         &kp CLCK                               &kp GRAVE   &kp MINUS   &kp EQUAL   &kp LBKT   &kp RBKT   &kp BSLH
  &trans       &kp K_UNDO     &kp K_CUT         &kp K_COPY          &kp K_PASTE    &trans         &out OUT_TOG   &trans   &kp TILDE   &kp UNDER   &kp PLUS    &kp LBRC   &kp RBRC   &kp PIPE
                              &rgb_ug RGB_TOG   &ext_power EP_TOG   &trans         &trans         &trans         &trans   &trans      &trans      &trans      &trans                        
,
  &inc_dec_kp C_VOL_UP C_VOL_DN
  &inc_dec_kp PG_UP PG_DN
)

ZMK_LAYER(realspace,
//    ┌─────────────┬────────┬────────┬────────┬────────┬────────┐                 ┌────────┬────────┬────────┬────────┬────────┬─────────────┐
//    │   &trans    │ &trans │ &trans │ &trans │ &trans │ &trans │                 │ &trans │ &trans │ &trans │ &trans │ &trans │   &kp N5    │
//    ├─────────────┼────────┼────────┼────────┼────────┼────────┤                 ├────────┼────────┼────────┼────────┼────────┼─────────────┤
//    │   &trans    │ &trans │ &trans │ &trans │ &trans │ &trans │                 │ &trans │ &trans │ &trans │ &trans │ &trans │   &trans    │
//    ├─────────────┼────────┼────────┼────────┼────────┼────────┤                 ├────────┼────────┼────────┼────────┼────────┼─────────────┤
//    │ &sys_reset  │ &trans │ &trans │ &trans │ &trans │ &trans │                 │ &trans │ &trans │ &trans │ &trans │ &trans │ &sys_reset  │
//    ├─────────────┼────────┼────────┼────────┼────────┼────────┼────────┬────────┼────────┼────────┼────────┼────────┼────────┼─────────────┤
//    │ &bootloader │ &trans │ &trans │ &trans │ &trans │ &trans │ &trans │ &trans │ &trans │ &trans │ &trans │ &trans │ &trans │ &bootloader │
//    └─────────────┴────────┼────────┼────────┼────────┼────────┼────────┼────────┼────────┼────────┼────────┼────────┼────────┴─────────────┘
//                           │ &trans │ &trans │ &trans │ &trans │ &trans │ &trans │ &trans │ &trans │ &trans │ &trans │                       
//                           └────────┴────────┴────────┴────────┴────────┴────────┴────────┴────────┴────────┴────────┘                       
        //
  &trans        &trans   &trans   &trans   &trans   &trans                     &trans   &trans   &trans   &trans   &trans   &kp N5     
  &trans        &trans   &trans   &trans   &trans   &trans                     &trans   &trans   &trans   &trans   &trans   &trans     
  &sys_reset    &trans   &trans   &trans   &trans   &trans                     &trans   &trans   &trans   &trans   &trans   &sys_reset 
  &bootloader   &trans   &trans   &trans   &trans   &trans   &trans   &trans   &trans   &trans   &trans   &trans   &trans   &bootloader
                         &trans   &trans   &trans   &trans   &trans   &trans   &trans   &trans   &trans   &trans                       
,
  &inc_dec_kp C_VOL_UP C_VOL_DN
  &inc_dec_kp PG_UP PG_DN
)

ZMK_LAYER(adjust,
//    ┌────────┬────────┬────────┬────────┬────────┬────────┐                 ┌────────┬────────┬────────┬────────┬────────┬────────┐
//    │ &trans │ &trans │ &trans │ &trans │ &trans │ &trans │                 │ &trans │ &trans │ &trans │ &trans │ &trans │ &kp N6 │
//    ├────────┼────────┼────────┼────────┼────────┼────────┤                 ├────────┼────────┼────────┼────────┼────────┼────────┤
//    │ &trans │ &trans │ &trans │ &trans │ &trans │ &trans │                 │ &trans │ &trans │ &trans │ &trans │ &trans │ &trans │
//    ├────────┼────────┼────────┼────────┼────────┼────────┤                 ├────────┼────────┼────────┼────────┼────────┼────────┤
//    │ &trans │ &trans │ &trans │ &trans │ &trans │ &trans │                 │ &trans │ &trans │ &trans │ &trans │ &trans │ &trans │
//    ├────────┼────────┼────────┼────────┼────────┼────────┼────────┬────────┼────────┼────────┼────────┼────────┼────────┼────────┤
//    │ &trans │ &trans │ &trans │ &trans │ &trans │ &trans │ &trans │ &trans │ &trans │ &trans │ &trans │ &trans │ &trans │ &trans │
//    └────────┴────────┼────────┼────────┼────────┼────────┼────────┼────────┼────────┼────────┼────────┼────────┼────────┴────────┘
//                      │ &trans │ &trans │ &trans │ &trans │ &trans │ &trans │ &trans │ &trans │ &trans │ &trans │                  
//                      └────────┴────────┴────────┴────────┴────────┴────────┴────────┴────────┴────────┴────────┘                  
        //
  &trans   &trans   &trans   &trans   &trans   &trans                     &trans   &trans   &trans   &trans   &trans   &kp N6
  &trans   &trans   &trans   &trans   &trans   &trans                     &trans   &trans   &trans   &trans   &trans   &trans
  &trans   &trans   &trans   &trans   &trans   &trans                     &trans   &trans   &trans   &trans   &trans   &trans
  &trans   &trans   &trans   &trans   &trans   &trans   &trans   &trans   &trans   &trans   &trans   &trans   &trans   &trans
                    &trans   &trans   &trans   &trans   &trans   &trans   &trans   &trans   &trans   &trans                  
,
  &inc_dec_kp C_VOL_UP C_VOL_DN
  &inc_dec_kp PG_UP PG_DN
)

ZMK_LAYER(subspace,
//    ┌─────────────────┬──────────────┬──────────────┬──────────────┬──────────────┬──────────────┐                 ┌────────┬────────┬────────┬────────┬────────┬────────┐
//    │     &trans      │    &trans    │    &trans    │    &trans    │    &trans    │    &trans    │                 │ &trans │ &trans │ &trans │ &trans │ &trans │ &kp N7 │
//    ├─────────────────┼──────────────┼──────────────┼──────────────┼──────────────┼──────────────┤                 ├────────┼────────┼────────┼────────┼────────┼────────┤
//    │ &rgb_ug RGB_TOG │    &trans    │    &trans    │ &out OUT_USB │ &out OUT_BLE │ &out OUT_TOG │                 │ &trans │ &trans │ &trans │ &trans │ &trans │ &trans │
//    ├─────────────────┼──────────────┼──────────────┼──────────────┼──────────────┼──────────────┤                 ├────────┼────────┼────────┼────────┼────────┼────────┤
//    │   &bt BT_CLR    │ &bt BT_SEL 0 │ &bt BT_SEL 1 │ &bt BT_SEL 2 │ &bt BT_SEL 3 │ &bt BT_SEL 4 │                 │ &trans │ &trans │ &trans │ &trans │ &trans │ &trans │
//    ├─────────────────┼──────────────┼──────────────┼──────────────┼──────────────┼──────────────┼────────┬────────┼────────┼────────┼────────┼────────┼────────┼────────┤
//    │     &trans      │ &bt BT_SEL 5 │ &bt BT_SEL 6 │ &bt BT_SEL 7 │ &bt BT_SEL 8 │ &bt BT_SEL 9 │ &trans │ &trans │ &trans │ &trans │ &trans │ &trans │ &trans │ &trans │
//    └─────────────────┴──────────────┼──────────────┼──────────────┼──────────────┼──────────────┼────────┼────────┼────────┼────────┼────────┼────────┼────────┴────────┘
//                                     │    &trans    │    &trans    │    &trans    │    &trans    │ &trans │ &trans │ &trans │ &trans │ &trans │ &trans │                  
//                                     └──────────────┴──────────────┴──────────────┴──────────────┴────────┴────────┴────────┴────────┴────────┴────────┘                  
        //
  &trans            &trans         &trans         &trans         &trans         &trans                           &trans   &trans   &trans   &trans   &trans   &kp N7
  &rgb_ug RGB_TOG   &trans         &trans         &out OUT_USB   &out OUT_BLE   &out OUT_TOG                     &trans   &trans   &trans   &trans   &trans   &trans
  &bt BT_CLR        &bt BT_SEL 0   &bt BT_SEL 1   &bt BT_SEL 2   &bt BT_SEL 3   &bt BT_SEL 4                     &trans   &trans   &trans   &trans   &trans   &trans
  &trans            &bt BT_SEL 5   &bt BT_SEL 6   &bt BT_SEL 7   &bt BT_SEL 8   &bt BT_SEL 9   &trans   &trans   &trans   &trans   &trans   &trans   &trans   &trans
                                   &trans         &trans         &trans         &trans         &trans   &trans   &trans   &trans   &trans   &trans                  
,
  &inc_dec_kp C_VOL_UP C_VOL_DN
  &inc_dec_kp PG_UP PG_DN
)

ZMK_LAYER(hyperspace,
//    ┌─────────────────┬─────────────────┬─────────────────┬─────────────────┬─────────────────┬────────┐                 ┌──────────┬───────────┬───────────┬───────────┬────────┬────────┐
//    │     &trans      │     &trans      │     &trans      │     &trans      │     &trans      │ &trans │                 │  &trans  │  &trans   │  &trans   │  &trans   │ &trans │ &kp N8 │
//    ├─────────────────┼─────────────────┼─────────────────┼─────────────────┼─────────────────┼────────┤                 ├──────────┼───────────┼───────────┼───────────┼────────┼────────┤
//    │ &rgb_ug RGB_TOG │     &trans      │     &trans      │     &trans      │     &trans      │ &trans │                 │  &trans  │  &trans   │  &trans   │  &trans   │ &trans │ &trans │
//    ├─────────────────┼─────────────────┼─────────────────┼─────────────────┼─────────────────┼────────┤                 ├──────────┼───────────┼───────────┼───────────┼────────┼────────┤
//    │ &rgb_ug RGB_EFF │ &rgb_ug RGB_HUI │ &rgb_ug RGB_SAI │ &rgb_ug RGB_BRI │ &rgb_ug RGB_SPI │ &trans │                 │ &kp LEFT │ &kp DOWN  │  &kp UP   │ &kp RIGHT │ &trans │ &trans │
//    ├─────────────────┼─────────────────┼─────────────────┼─────────────────┼─────────────────┼────────┼────────┬────────┼──────────┼───────────┼───────────┼───────────┼────────┼────────┤
//    │ &rgb_ug RGB_EFR │ &rgb_ug RGB_HUD │ &rgb_ug RGB_SAD │ &rgb_ug RGB_BRD │ &rgb_ug RGB_SPD │ &trans │ &trans │ &trans │ &kp HOME │ &kp PG_DN │ &kp PG_UP │  &kp END  │ &trans │ &trans │
//    └─────────────────┴─────────────────┼─────────────────┼─────────────────┼─────────────────┼────────┼────────┼────────┼──────────┼───────────┼───────────┼───────────┼────────┴────────┘
//                                        │     &trans      │     &trans      │     &trans      │ &trans │ &trans │ &trans │  &trans  │  &trans   │  &trans   │  &trans   │                  
//                                        └─────────────────┴─────────────────┴─────────────────┴────────┴────────┴────────┴──────────┴───────────┴───────────┴───────────┘                  
        //
  &trans            &trans            &trans            &trans            &trans            &trans                     &trans     &trans      &trans      &trans      &trans   &kp N8
  &rgb_ug RGB_TOG   &trans            &trans            &trans            &trans            &trans                     &trans     &trans      &trans      &trans      &trans   &trans
  &rgb_ug RGB_EFF   &rgb_ug RGB_HUI   &rgb_ug RGB_SAI   &rgb_ug RGB_BRI   &rgb_ug RGB_SPI   &trans                     &kp LEFT   &kp DOWN    &kp UP      &kp RIGHT   &trans   &trans
  &rgb_ug RGB_EFR   &rgb_ug RGB_HUD   &rgb_ug RGB_SAD   &rgb_ug RGB_BRD   &rgb_ug RGB_SPD   &trans   &trans   &trans   &kp HOME   &kp PG_DN   &kp PG_UP   &kp END     &trans   &trans
                                      &trans            &trans            &trans            &trans   &trans   &trans   &trans     &trans      &trans      &trans                     
,
  &inc_dec_kp C_VOL_UP C_VOL_DN
  &inc_dec_kp PG_UP PG_DN
)

ZMK_LAYER(knownspace,
//    ┌────────┬───────────────────┬───────────────────┬────────┬────────┬────────┐                 ┌────────┬────────┬────────┬────────┬────────┬────────┐
//    │ &trans │      &trans       │      &trans       │ &trans │ &trans │ &trans │                 │ &trans │ &trans │ &trans │ &trans │ &trans │ &kp B  │
//    ├────────┼───────────────────┼───────────────────┼────────┼────────┼────────┤                 ├────────┼────────┼────────┼────────┼────────┼────────┤
//    │ &trans │ &ext_power EP_TOG │ &ext_power EP_OFF │ &trans │ &trans │ &trans │                 │ &trans │ &trans │ &trans │ &trans │ &trans │ &trans │
//    ├────────┼───────────────────┼───────────────────┼────────┼────────┼────────┤                 ├────────┼────────┼────────┼────────┼────────┼────────┤
//    │ &trans │      &trans       │      &trans       │ &trans │ &trans │ &trans │                 │ &trans │ &trans │ &trans │ &trans │ &trans │ &trans │
//    ├────────┼───────────────────┼───────────────────┼────────┼────────┼────────┼────────┬────────┼────────┼────────┼────────┼────────┼────────┼────────┤
//    │ &trans │      &trans       │      &trans       │ &trans │ &trans │ &trans │ &trans │ &trans │ &trans │ &trans │ &trans │ &trans │ &trans │ &trans │
//    └────────┴───────────────────┼───────────────────┼────────┼────────┼────────┼────────┼────────┼────────┼────────┼────────┼────────┼────────┴────────┘
//                                 │      &trans       │ &trans │ &trans │ &trans │ &trans │ &trans │ &trans │ &trans │ &trans │ &trans │                  
//                                 └───────────────────┴────────┴────────┴────────┴────────┴────────┴────────┴────────┴────────┴────────┘                  
        //
  &trans   &trans              &trans              &trans   &trans   &trans                     &trans   &trans   &trans   &trans   &trans   &kp B 
  &trans   &ext_power EP_TOG   &ext_power EP_OFF   &trans   &trans   &trans                     &trans   &trans   &trans   &trans   &trans   &trans
  &trans   &trans              &trans              &trans   &trans   &trans                     &trans   &trans   &trans   &trans   &trans   &trans
  &trans   &trans              &trans              &trans   &trans   &trans   &trans   &trans   &trans   &trans   &trans   &trans   &trans   &trans
                               &trans              &trans   &trans   &trans   &trans   &trans   &trans   &trans   &trans   &trans                  
,
  &inc_dec_kp C_VOL_UP C_VOL_DN
  &inc_dec_kp PG_UP PG_DN
)

ZMK_LAYER(cyberspace,
//    ┌────────┬────────┬────────┬────────┬────────┬────────┐                 ┌────────┬────────┬────────┬────────┬────────┬────────┐
//    │ &trans │ &trans │ &trans │ &trans │ &trans │ &trans │                 │ &trans │ &trans │ &trans │ &trans │ &trans │ &kp C  │
//    ├────────┼────────┼────────┼────────┼────────┼────────┤                 ├────────┼────────┼────────┼────────┼────────┼────────┤
//    │ &trans │ &trans │ &trans │ &trans │ &trans │ &trans │                 │ &trans │ &trans │ &trans │ &trans │ &trans │ &trans │
//    ├────────┼────────┼────────┼────────┼────────┼────────┤                 ├────────┼────────┼────────┼────────┼────────┼────────┤
//    │ &trans │ &trans │ &trans │ &trans │ &trans │ &trans │                 │ &trans │ &trans │ &trans │ &trans │ &trans │ &trans │
//    ├────────┼────────┼────────┼────────┼────────┼────────┼────────┬────────┼────────┼────────┼────────┼────────┼────────┼────────┤
//    │ &trans │ &trans │ &trans │ &trans │ &trans │ &trans │ &trans │ &trans │ &trans │ &trans │ &trans │ &trans │ &trans │ &trans │
//    └────────┴────────┼────────┼────────┼────────┼────────┼────────┼────────┼────────┼────────┼────────┼────────┼────────┴────────┘
//                      │ &trans │ &trans │ &trans │ &trans │ &trans │ &trans │ &trans │ &trans │ &trans │ &trans │                  
//                      └────────┴────────┴────────┴────────┴────────┴────────┴────────┴────────┴────────┴────────┘                  
        //
  &trans   &trans   &trans   &trans   &trans   &trans                     &trans   &trans   &trans   &trans   &trans   &kp C 
  &trans   &trans   &trans   &trans   &trans   &trans                     &trans   &trans   &trans   &trans   &trans   &trans
  &trans   &trans   &trans   &trans   &trans   &trans                     &trans   &trans   &trans   &trans   &trans   &trans
  &trans   &trans   &trans   &trans   &trans   &trans   &trans   &trans   &trans   &trans   &trans   &trans   &trans   &trans
                    &trans   &trans   &trans   &trans   &trans   &trans   &trans   &trans   &trans   &trans                  
        ,
        &inc_dec_kp C_VOL_UP C_VOL_DN
        &inc_dec_kp PG_UP PG_DN
        )
ZMK_LAYER(slipspace,
//    ┌────────┬────────┬────────┬────────┬────────┬────────┐                 ┌────────┬────────┬────────┬────────┬────────┬────────┐
//    │ &trans │ &trans │ &trans │ &trans │ &trans │ &trans │                 │ &trans │ &trans │ &trans │ &trans │ &trans │ &kp N9 │
//    ├────────┼────────┼────────┼────────┼────────┼────────┤                 ├────────┼────────┼────────┼────────┼────────┼────────┤
//    │ &trans │ &trans │ &trans │ &trans │ &trans │ &trans │                 │ &trans │ &trans │ &trans │ &trans │ &trans │ &trans │
//    ├────────┼────────┼────────┼────────┼────────┼────────┤                 ├────────┼────────┼────────┼────────┼────────┼────────┤
//    │ &trans │ &trans │ &trans │ &trans │ &trans │ &trans │                 │ &trans │ &trans │ &trans │ &trans │ &trans │ &trans │
//    ├────────┼────────┼────────┼────────┼────────┼────────┼────────┬────────┼────────┼────────┼────────┼────────┼────────┼────────┤
//    │ &trans │ &trans │ &trans │ &trans │ &trans │ &trans │ &trans │ &trans │ &trans │ &trans │ &trans │ &trans │ &trans │ &trans │
//    └────────┴────────┼────────┼────────┼────────┼────────┼────────┼────────┼────────┼────────┼────────┼────────┼────────┴────────┘
//                      │ &trans │ &trans │ &trans │ &trans │ &trans │ &trans │ &trans │ &trans │ &trans │ &trans │                  
//                      └────────┴────────┴────────┴────────┴────────┴────────┴────────┴────────┴────────┴────────┘                  
        //
  &trans   &trans   &trans   &trans   &trans   &trans                     &trans   &trans   &trans   &trans   &trans   &kp N9
  &trans   &trans   &trans   &trans   &trans   &trans                     &trans   &trans   &trans   &trans   &trans   &trans
  &trans   &trans   &trans   &trans   &trans   &trans                     &trans   &trans   &trans   &trans   &trans   &trans
  &trans   &trans   &trans   &trans   &trans   &trans   &trans   &trans   &trans   &trans   &trans   &trans   &trans   &trans
                    &trans   &trans   &trans   &trans   &trans   &trans   &trans   &trans   &trans   &trans                  
,
  &inc_dec_kp C_VOL_UP C_VOL_DN
  &inc_dec_kp PG_UP PG_DN
)

ZMK_LAYER(foldspace,
//    ┌────────┬────────┬────────┬────────┬────────┬────────┐                 ┌────────┬────────┬────────┬────────┬────────┬────────┐
//    │ &trans │ &trans │ &trans │ &trans │ &trans │ &trans │                 │ &trans │ &trans │ &trans │ &trans │ &trans │ &kp A  │
//    ├────────┼────────┼────────┼────────┼────────┼────────┤                 ├────────┼────────┼────────┼────────┼────────┼────────┤
//    │ &trans │ &trans │ &trans │ &trans │ &trans │ &trans │                 │ &trans │ &trans │ &trans │ &trans │ &trans │ &trans │
//    ├────────┼────────┼────────┼────────┼────────┼────────┤                 ├────────┼────────┼────────┼────────┼────────┼────────┤
//    │ &trans │ &trans │ &trans │ &trans │ &trans │ &trans │                 │ &trans │ &trans │ &trans │ &trans │ &trans │ &trans │
//    ├────────┼────────┼────────┼────────┼────────┼────────┼────────┬────────┼────────┼────────┼────────┼────────┼────────┼────────┤
//    │ &trans │ &trans │ &trans │ &trans │ &trans │ &trans │ &trans │ &trans │ &trans │ &trans │ &trans │ &trans │ &trans │ &trans │
//    └────────┴────────┼────────┼────────┼────────┼────────┼────────┼────────┼────────┼────────┼────────┼────────┼────────┴────────┘
//                      │ &trans │ &trans │ &trans │ &trans │ &trans │ &trans │ &trans │ &trans │ &trans │ &trans │                  
//                      └────────┴────────┴────────┴────────┴────────┴────────┴────────┴────────┴────────┴────────┘                  
        //
  &trans   &trans   &trans   &trans   &trans   &trans                     &trans   &trans   &trans   &trans   &trans   &kp A 
  &trans   &trans   &trans   &trans   &trans   &trans                     &trans   &trans   &trans   &trans   &trans   &trans
  &trans   &trans   &trans   &trans   &trans   &trans                     &trans   &trans   &trans   &trans   &trans   &trans
  &trans   &trans   &trans   &trans   &trans   &trans   &trans   &trans   &trans   &trans   &trans   &trans   &trans   &trans
                    &trans   &trans   &trans   &trans   &trans   &trans   &trans   &trans   &trans   &trans                  
,
  &inc_dec_kp C_VOL_UP C_VOL_DN
  &inc_dec_kp PG_UP PG_DN
)

ZMK_LAYER(blackhole,
//    ┌────────┬────────┬────────┬────────┬────────┬────────┐                 ┌────────┬────────┬────────┬────────┬────────┬────────┐
//    │ &trans │ &trans │ &trans │ &trans │ &trans │ &trans │                 │ &trans │ &trans │ &trans │ &trans │ &trans │ &kp D  │
//    ├────────┼────────┼────────┼────────┼────────┼────────┤                 ├────────┼────────┼────────┼────────┼────────┼────────┤
//    │ &trans │ &trans │ &trans │ &trans │ &trans │ &trans │                 │ &trans │ &trans │ &trans │ &trans │ &trans │ &trans │
//    ├────────┼────────┼────────┼────────┼────────┼────────┤                 ├────────┼────────┼────────┼────────┼────────┼────────┤
//    │ &trans │ &trans │ &trans │ &trans │ &trans │ &trans │                 │ &trans │ &trans │ &trans │ &trans │ &trans │ &trans │
//    ├────────┼────────┼────────┼────────┼────────┼────────┼────────┬────────┼────────┼────────┼────────┼────────┼────────┼────────┤
//    │ &trans │ &trans │ &trans │ &trans │ &trans │ &trans │ &trans │ &trans │ &trans │ &trans │ &trans │ &trans │ &trans │ &trans │
//    └────────┴────────┼────────┼────────┼────────┼────────┼────────┼────────┼────────┼────────┼────────┼────────┼────────┴────────┘
//                      │ &trans │ &trans │ &trans │ &trans │ &trans │ &trans │ &trans │ &trans │ &trans │ &trans │                  
//                      └────────┴────────┴────────┴────────┴────────┴────────┴────────┴────────┴────────┴────────┘                  
        //
  &trans   &trans   &trans   &trans   &trans   &trans                     &trans   &trans   &trans   &trans   &trans   &kp D 
  &trans   &trans   &trans   &trans   &trans   &trans                     &trans   &trans   &trans   &trans   &trans   &trans
  &trans   &trans   &trans   &trans   &trans   &trans                     &trans   &trans   &trans   &trans   &trans   &trans
  &trans   &trans   &trans   &trans   &trans   &trans   &trans   &trans   &trans   &trans   &trans   &trans   &trans   &trans
                    &trans   &trans   &trans   &trans   &trans   &trans   &trans   &trans   &trans   &trans                  
,
  &inc_dec_kp C_VOL_UP C_VOL_DN
  &inc_dec_kp PG_UP PG_DN
)

ZMK_LAYER(wormhole,
//    ┌────────┬────────┬────────┬────────┬────────┬────────┐                 ┌────────┬────────┬────────┬────────┬────────┬────────┐
//    │ &trans │ &trans │ &trans │ &trans │ &trans │ &trans │                 │ &trans │ &trans │ &trans │ &trans │ &trans │ &kp E  │
//    ├────────┼────────┼────────┼────────┼────────┼────────┤                 ├────────┼────────┼────────┼────────┼────────┼────────┤
//    │ &trans │ &trans │ &trans │ &trans │ &trans │ &trans │                 │ &trans │ &trans │ &trans │ &trans │ &trans │ &trans │
//    ├────────┼────────┼────────┼────────┼────────┼────────┤                 ├────────┼────────┼────────┼────────┼────────┼────────┤
//    │ &trans │ &trans │ &trans │ &trans │ &trans │ &trans │                 │ &trans │ &trans │ &trans │ &trans │ &trans │ &trans │
//    ├────────┼────────┼────────┼────────┼────────┼────────┼────────┬────────┼────────┼────────┼────────┼────────┼────────┼────────┤
//    │ &trans │ &trans │ &trans │ &trans │ &trans │ &trans │ &trans │ &trans │ &trans │ &trans │ &trans │ &trans │ &trans │ &trans │
//    └────────┴────────┼────────┼────────┼────────┼────────┼────────┼────────┼────────┼────────┼────────┼────────┼────────┴────────┘
//                      │ &trans │ &trans │ &trans │ &trans │ &trans │ &trans │ &trans │ &trans │ &trans │ &trans │                  
//                      └────────┴────────┴────────┴────────┴────────┴────────┴────────┴────────┴────────┴────────┘                  
        //
  &trans   &trans   &trans   &trans   &trans   &trans                     &trans   &trans   &trans   &trans   &trans   &kp E 
  &trans   &trans   &trans   &trans   &trans   &trans                     &trans   &trans   &trans   &trans   &trans   &trans
  &trans   &trans   &trans   &trans   &trans   &trans                     &trans   &trans   &trans   &trans   &trans   &trans
  &trans   &trans   &trans   &trans   &trans   &trans   &trans   &trans   &trans   &trans   &trans   &trans   &trans   &trans
                    &trans   &trans   &trans   &trans   &trans   &trans   &trans   &trans   &trans   &trans                  
,
  &inc_dec_kp C_VOL_UP C_VOL_DN
  &inc_dec_kp PG_UP PG_DN
)

ZMK_LAYER(warp,
//    ┌────────┬────────┬────────┬────────┬────────┬────────┐                 ┌────────┬────────┬────────┬────────┬────────┬────────┐
//    │ &trans │ &trans │ &trans │ &trans │ &trans │ &trans │                 │ &trans │ &trans │ &trans │ &trans │ &trans │ &kp F  │
//    ├────────┼────────┼────────┼────────┼────────┼────────┤                 ├────────┼────────┼────────┼────────┼────────┼────────┤
//    │ &trans │ &trans │ &trans │ &trans │ &trans │ &trans │                 │ &trans │ &trans │ &trans │ &trans │ &trans │ &trans │
//    ├────────┼────────┼────────┼────────┼────────┼────────┤                 ├────────┼────────┼────────┼────────┼────────┼────────┤
//    │ &trans │ &trans │ &trans │ &trans │ &trans │ &trans │                 │ &trans │ &trans │ &trans │ &trans │ &trans │ &trans │
//    ├────────┼────────┼────────┼────────┼────────┼────────┼────────┬────────┼────────┼────────┼────────┼────────┼────────┼────────┤
//    │ &trans │ &trans │ &trans │ &trans │ &trans │ &trans │ &trans │ &trans │ &trans │ &trans │ &trans │ &trans │ &trans │ &trans │
//    └────────┴────────┼────────┼────────┼────────┼────────┼────────┼────────┼────────┼────────┼────────┼────────┼────────┴────────┘
//                      │ &trans │ &trans │ &trans │ &trans │ &trans │ &trans │ &trans │ &trans │ &trans │ &trans │                  
//                      └────────┴────────┴────────┴────────┴────────┴────────┴────────┴────────┴────────┴────────┘                  
        //
  &trans   &trans   &trans   &trans   &trans   &trans                     &trans   &trans   &trans   &trans   &trans   &kp F 
  &trans   &trans   &trans   &trans   &trans   &trans                     &trans   &trans   &trans   &trans   &trans   &trans
  &trans   &trans   &trans   &trans   &trans   &trans                     &trans   &trans   &trans   &trans   &trans   &trans
  &trans   &trans   &trans   &trans   &trans   &trans   &trans   &trans   &trans   &trans   &trans   &trans   &trans   &trans
                    &trans   &trans   &trans   &trans   &trans   &trans   &trans   &trans   &trans   &trans                  
,
        &inc_dec_kp C_VOL_UP C_VOL_DN
        &inc_dec_kp PG_UP PG_DN
)
